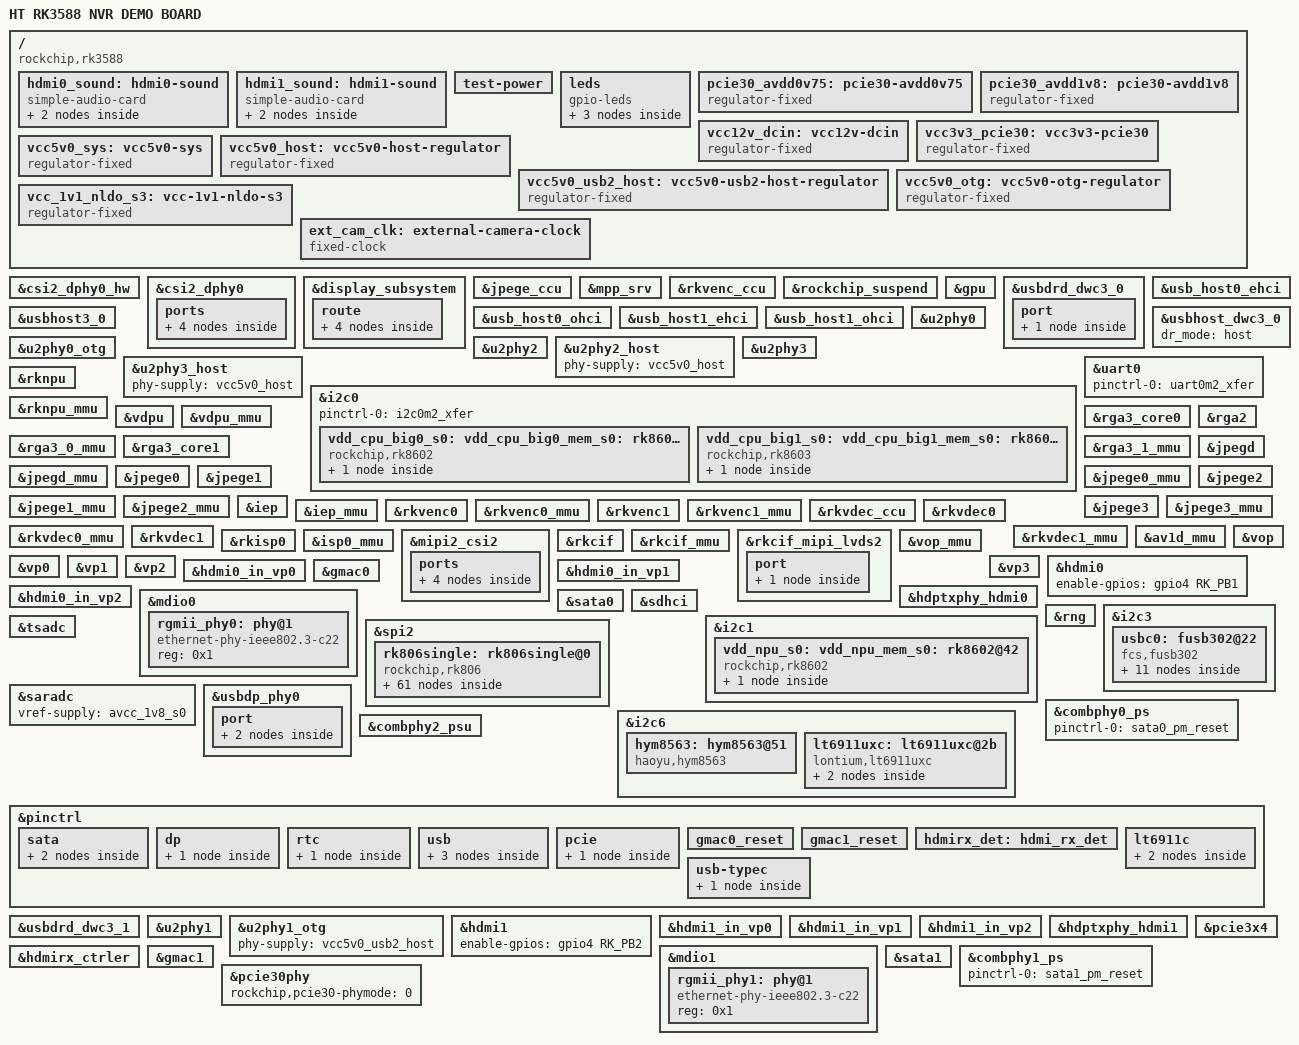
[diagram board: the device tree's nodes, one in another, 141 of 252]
// SPDX-License-Identifier: (GPL-2.0+ OR MIT)
/*
 * Copyright (c) 2026 Rockchip Electronics Co., Ltd.
 *
 */

/dts-v1/;


#include <dt-bindings/usb/pd.h>
#include "rk3588.dtsi"
#include "rk3588-nvr.dtsi"
#include "rk3588-linux.dtsi"

/ {
	serial-number = "b8003718ffaabed8";
	model = "HT RK3588 NVR DEMO BOARD";
	compatible = "rockchip,rk3588";

	hdmi0_sound: hdmi0-sound {
		status = "disabled";
		compatible = "simple-audio-card";
		simple-audio-card,format = "i2s";
		simple-audio-card,mclk-fs = <128>;
		simple-audio-card,name = "rockchip,hdmi0";

		simple-audio-card,cpu {
			sound-dai = <&i2s5_8ch>;
		};
		simple-audio-card,codec {
			sound-dai = <&hdmi0>;
		};
	};
	hdmi1_sound: hdmi1-sound {
		status = "disabled";
		compatible = "simple-audio-card";
		simple-audio-card,format = "i2s";
		simple-audio-card,mclk-fs = <128>;
		simple-audio-card,name = "rockchip,hdmi1";

		simple-audio-card,cpu {
			sound-dai = <&i2s6_8ch>;
		};
		simple-audio-card,codec {
			sound-dai = <&hdmi1>;
		};
	};
	test-power {
		status = "okay";
	};
	leds: leds {
		compatible = "gpio-leds";
		hdd_led: hdd-led {
			gpios = <&gpio3 RK_PC1 GPIO_ACTIVE_HIGH>;
			default-state = "off";
		};
		net_led: net-led {
			gpios = <&gpio3 RK_PC0 GPIO_ACTIVE_HIGH>;
			default-state = "off";
		};
		work_led: work-led {
			gpios = <&gpio3 RK_PB7 GPIO_ACTIVE_HIGH>;
			linux,default-trigger = "heartbeat";
		};
	};
	pcie30_avdd0v75: pcie30-avdd0v75 {
		compatible = "regulator-fixed";
		regulator-name = "pcie30_avdd0v75";
		regulator-boot-on;
		regulator-always-on;
		regulator-min-microvolt = <750000>;
		regulator-max-microvolt = <750000>;
		vin-supply = <&nldo5_s0>;
	};
	pcie30_avdd1v8: pcie30-avdd1v8 {
		compatible = "regulator-fixed";
		regulator-name = "pcie30_avdd1v8";
		regulator-boot-on;
		regulator-always-on;
		regulator-min-microvolt = <1800000>;
		regulator-max-microvolt = <1800000>;
		vin-supply = <&avcc_1v8_s0>;
	};
	vcc12v_dcin: vcc12v-dcin {
		compatible = "regulator-fixed";
		regulator-name = "vcc12v_dcin";
		regulator-always-on;
		regulator-boot-on;
		regulator-min-microvolt = <12000000>;
		regulator-max-microvolt = <12000000>;
	};
	vcc3v3_pcie30: vcc3v3-pcie30 {
		compatible = "regulator-fixed";
		regulator-name = "vcc3v3_pcie30";
		regulator-min-microvolt = <3300000>;
		regulator-max-microvolt = <3300000>;
		enable-active-high;
		gpios = <&gpio2 RK_PB4 GPIO_ACTIVE_HIGH>;
		startup-delay-us = <7500>;
		vin-supply = <&vcc12v_dcin>;
	};
	vcc5v0_sys: vcc5v0-sys {
		compatible = "regulator-fixed";
		regulator-name = "vcc5v0_sys";
		regulator-always-on;
		regulator-boot-on;
		regulator-min-microvolt = <5000000>;
		regulator-max-microvolt = <5000000>;
		vin-supply = <&vcc12v_dcin>;
	};
	vcc5v0_host: vcc5v0-host-regulator {
		compatible = "regulator-fixed";
		regulator-name = "vcc5v0_host";
		regulator-boot-on;
		regulator-always-on;
		regulator-min-microvolt = <5000000>;
		regulator-max-microvolt = <5000000>;
		enable-active-high;
		gpio = <&gpio3 RK_PC1 GPIO_ACTIVE_HIGH>;
		vin-supply = <&vcc5v0_sys>;
		pinctrl-names = "default";
		pinctrl-0 = <&vcc5v0_host_en>;
	};
	vcc5v0_usb2_host: vcc5v0-usb2-host-regulator {
		compatible = "regulator-fixed";
		regulator-name = "vcc5v0_usb2_host";
		regulator-boot-on;
		regulator-always-on;
		regulator-min-microvolt = <5000000>;
		regulator-max-microvolt = <5000000>;
		enable-active-high;
		gpio = <&gpio3 RK_PC0 GPIO_ACTIVE_HIGH>;
		vin-supply = <&vcc5v0_sys>;
		pinctrl-names = "default";
		pinctrl-0 = <&vcc5v0_usb2_host_en>;
	};
	vcc5v0_otg: vcc5v0-otg-regulator {
		compatible = "regulator-fixed";
		regulator-name = "vcc5v0_otg";
		regulator-min-microvolt = <5000000>;
		regulator-max-microvolt = <5000000>;
		enable-active-high;
		gpio = <&gpio4 RK_PA7 GPIO_ACTIVE_HIGH>;
		vin-supply = <&vcc5v0_sys>;
		pinctrl-names = "default";
		pinctrl-0 = <&vcc5v0_otg_en>;
	};
	vcc_1v1_nldo_s3: vcc-1v1-nldo-s3 {
		compatible = "regulator-fixed";
		regulator-name = "vcc_1v1_nldo_s3";
		regulator-always-on;
		regulator-boot-on;
		regulator-min-microvolt = <1100000>;
		regulator-max-microvolt = <1100000>;
		vin-supply = <&vcc5v0_sys>;
	};
	ext_cam_clk: external-camera-clock {
		status = "okay";
		compatible = "fixed-clock";
		clock-frequency = <27000000>;
		clock-output-names = "CLK_CAMERA_27MHZ";
		#clock-cells = <0>;
	};
};

&csi2_dphy0_hw {
	status = "okay";
};

&csi2_dphy0 {
	status = "okay";

	ports {
		#address-cells = <1>;
		#size-cells = <0>;

		port@0 {
			reg = <0>;
			#address-cells = <1>;
			#size-cells = <0>;

			hdmi_mipi_in: endpoint@1 {
				reg = <1>;
				remote-endpoint = <&lt6911uxc_out0>;
				data-lanes = <1 2>;
			};
		};

		port@1 {
			reg = <1>;
			#address-cells = <1>;
			#size-cells = <0>;

			csidphy0_out: endpoint@0 {
				reg = <0>;
				remote-endpoint = <&mipi2_csi2_input>;
			};
		};
	};
};

&display_subsystem {
	route {

		route_dp0: route-dp0 {
			status = "okay";
			logo,uboot = "logo.bmp";
			logo,kernel = "logo_kernel.bmp";
			logo,mode = "center";
			charge_logo,mode = "center";
			connect = <&vp2_out_dp0>;
		};

		route_hdmi0: route-hdmi0 {
			status = "okay";
			logo,uboot = "logo.bmp";
			logo,kernel = "logo_kernel.bmp";
			logo,mode = "center";
			charge_logo,mode = "center";
			connect = <&vp2_out_hdmi0>;
		};

		route_dp1: route-dp1 {
			status = "okay";
			logo,uboot = "logo.bmp";
			logo,kernel = "logo_kernel.bmp";
			logo,mode = "center";
			charge_logo,mode = "center";
			connect = <&vp2_out_dp1>;
		};

		route_hdmi1: route-hdmi1 {
			status = "okay";
			logo,uboot = "logo.bmp";
			logo,kernel = "logo_kernel.bmp";
			logo,mode = "center";
			charge_logo,mode = "center";
			connect = <&vp2_out_hdmi1>;
		};
	};
};
&jpege_ccu {
	status = "okay";
};
&mpp_srv {
	status = "okay";
};
&rkvenc_ccu {
	status = "okay";
};
&rockchip_suspend {
	status = "okay";
	rockchip,sleep-debug-en = <1>;
	rockchip,virtual-poweroff = <1>;
	rockchip,sleep-mode-config = <
		(0
		| RKPM_SLP_ARMOFF_DDRPD
		)
	>;
	rockchip,wakeup-config = <
		(0
		| RKPM_CPU0_WKUP_EN
		| RKPM_GPIO_WKUP_EN
		)
	>;
};
&gpu {
	mali-supply = <&vdd_gpu_s0>;
	mem-supply = <&vdd_gpu_mem_s0>;
	status = "okay";
};
&usbdrd_dwc3_0 {
	dr_mode = "otg";
	usb-role-switch;
	status = "okay";
	port {
		#address-cells = <1>;
		#size-cells = <0>;
		dwc3_0_role_switch: endpoint@0 {
			reg = <0>;
			remote-endpoint = <&usbc0_role_sw>;
		};
	};
};
&usb_host0_ehci {
	status = "okay";
};
&usb_host0_ohci {
	status = "okay";
};
&usb_host1_ehci {
	status = "okay";
};

&usb_host1_ohci {
	status = "okay";
};
&usbhost3_0 {
	status = "okay";
};
&usbhost_dwc3_0 {
	dr_mode = "host";
	status = "okay";
};
&u2phy0 {
	status = "okay";
};
&u2phy0_otg {
	vbus-supply = <&vcc5v0_otg>;
	rockchip,typec-vbus-det;
	status = "okay";
};
&u2phy2 {
	status = "okay";
};
&u2phy2_host {
	phy-supply = <&vcc5v0_host>;
	status = "okay";
};
&u2phy3 {
	status = "okay";
};
&u2phy3_host {
	phy-supply = <&vcc5v0_host>;
	status = "okay";
};
&i2c0 {
	status = "okay";
	pinctrl-names = "default";
	pinctrl-0 = <&i2c0m2_xfer>;
	
	vdd_cpu_big0_s0: vdd_cpu_big0_mem_s0: rk8602@42 {
		compatible = "rockchip,rk8602";
		reg = <0x42>;
		vin-supply = <&vcc5v0_sys>;
		regulator-compatible = "rk860x-reg";
		regulator-name = "vdd_cpu_big0_s0";
		regulator-min-microvolt = <550000>;
		regulator-max-microvolt = <1050000>;
		regulator-ramp-delay = <2300>;
		rockchip,suspend-voltage-selector = <1>;
		regulator-boot-on;
		regulator-always-on;
		regulator-state-mem {
			regulator-off-in-suspend;
		};
	};

	vdd_cpu_big1_s0: vdd_cpu_big1_mem_s0: rk8603@43 {
		compatible = "rockchip,rk8603";
		reg = <0x43>;
		vin-supply = <&vcc5v0_sys>;
		regulator-compatible = "rk860x-reg";
		regulator-name = "vdd_cpu_big1_s0";
		regulator-min-microvolt = <550000>;
		regulator-max-microvolt = <1050000>;
		regulator-ramp-delay = <2300>;
		rockchip,suspend-voltage-selector = <1>;
		regulator-boot-on;
		regulator-always-on;
		regulator-state-mem {
			regulator-off-in-suspend;
		};
	};
};
&uart0 {
    status = "okay";
    pinctrl-names = "default";
    pinctrl-0 = <&uart0m2_xfer>;

};
&rknpu {
	rknpu-supply = <&vdd_npu_s0>;
	mem-supply = <&vdd_npu_mem_s0>;
	status = "okay";
};
&rknpu_mmu {
	status = "okay";
};
&vdpu {
	status = "okay";
};

&vdpu_mmu {
	status = "okay";
};
&rga3_core0 {
	status = "okay";
};

&rga3_0_mmu {
	status = "okay";
};

&rga3_core1 {
	status = "okay";
};

&rga3_1_mmu {
	status = "okay";
};

&rga2 {
	status = "okay";
};
&jpegd {
	status = "okay";
};

&jpegd_mmu {
	status = "okay";
};
&jpege0 {
	status = "okay";
};
&jpege0_mmu {
	status = "okay";
};
&jpege1 {
	status = "okay";
};
&jpege1_mmu {
	status = "okay";
};
&jpege2 {
	status = "okay";
};
&jpege2_mmu {
	status = "okay";
};
&jpege3 {
	status = "okay";
};
&jpege3_mmu {
	status = "okay";
};
&iep {
	status = "okay";
};
&iep_mmu {
	status = "okay";
};
&rkvenc_ccu {
	status = "okay";
};
&rkvenc0 {
	status = "okay";
};
&rkvenc0_mmu {
	status = "okay";
};
&rkvenc1 {
	status = "okay";
};
&rkvenc1_mmu {
	status = "okay";
};
&rkvenc_ccu {
	status = "okay";
};
&rkvdec_ccu {
	status = "okay";
};
&rkvdec0 {
	status = "okay";
};
&rkvdec0_mmu {
	status = "okay";
};
&rkvdec1 {
	status = "okay";
};
&rkvdec1_mmu {
	status = "okay";
};
&av1d_mmu {
	status = "okay";
};
&rkisp0 {
	status = "okay";
};
&isp0_mmu {
	status = "okay";
};
&mipi2_csi2 {
	status = "okay";

	ports {
		#address-cells = <1>;
		#size-cells = <0>;

		port@0 {
			reg = <0>;
			#address-cells = <1>;
			#size-cells = <0>;

			mipi2_csi2_input: endpoint@1 {
				reg = <1>;
				remote-endpoint = <&csidphy0_out>;
			};
		};

		port@1 {
			reg = <1>;
			#address-cells = <1>;
			#size-cells = <0>;

			mipi2_csi2_output: endpoint@0 {
				reg = <0>;
				remote-endpoint = <&cif_mipi_in2>;
			};
		};
	};
};
&rkcif {
	status = "okay";
};
&rkcif_mmu {
	status = "okay";
};
&rkcif_mipi_lvds2 {
	status = "okay";

	port {
		cif_mipi_in2: endpoint {
			remote-endpoint = <&mipi2_csi2_output>;
		};
	};
};
&vop {
	assigned-clocks = <&cru ACLK_VOP>;
	assigned-clock-rates = <800000000>;
	status = "okay";
	skip-ref-fb;
};

&vop_mmu {
	status = "okay";
};

&vp0 {
	rockchip,plane-mask = <(1 << ROCKCHIP_VOP2_CLUSTER0 | 1 << ROCKCHIP_VOP2_ESMART0)>;
	rockchip,primary-plane = <ROCKCHIP_VOP2_ESMART0>;
};

&vp1 {
	rockchip,plane-mask = <(1 << ROCKCHIP_VOP2_CLUSTER1 | 1 << ROCKCHIP_VOP2_ESMART1)>;
	rockchip,primary-plane = <ROCKCHIP_VOP2_ESMART1>;
};

&vp2 {
	rockchip,plane-mask = <(1 << ROCKCHIP_VOP2_CLUSTER2 | 1 << ROCKCHIP_VOP2_ESMART2)>;
	rockchip,primary-plane = <ROCKCHIP_VOP2_ESMART2>;
};

&vp3 {
	rockchip,plane-mask = <(1 << ROCKCHIP_VOP2_CLUSTER3 | 1 << ROCKCHIP_VOP2_ESMART3)>;
	rockchip,primary-plane = <ROCKCHIP_VOP2_ESMART3>;

	assigned-clocks = <&cru DCLK_VOP3>;
	assigned-clock-parents = <&cru PLL_AUPLL>;
};
&vop_mmu {
	status = "okay";
};

&hdmi0 {
	enable-gpios = <&gpio4 RK_PB1 GPIO_ACTIVE_HIGH>;
	status = "okay";
};

&hdmi0_in_vp0 {
	status = "okay";
};

&hdmi0_in_vp1 {
	status = "okay";
};

&hdmi0_in_vp2 {
	status = "okay";
};
&hdmi0_sound {
	status = "okay";
};
&hdptxphy_hdmi0 {
	status = "okay";
};
&gmac0 {
	/* Use rgmii-rxid mode to disable rx delay inside Soc */
	phy-mode = "rgmii-rxid";
	clock_in_out = "output";

	snps,reset-gpio = <&gpio4 RK_PB3 GPIO_ACTIVE_LOW>;
	snps,reset-active-low;
	/* Reset time is 20ms, 100ms for rtl8211f */
	snps,reset-delays-us = <0 20000 100000>;

	pinctrl-names = "default";
	pinctrl-0 = <&gmac0_miim
		     &gmac0_tx_bus2
		     &gmac0_rx_bus2
		     &gmac0_rgmii_clk
		     &gmac0_rgmii_bus>;

	tx_delay = <0x44>;

	phy-handle = <&rgmii_phy0>;
	status = "okay";
};
&mdio0 {
	rgmii_phy0: phy@1 {
		compatible = "ethernet-phy-ieee802.3-c22";
		reg = <0x1>;
	};
};
&sata0 {
	status = "okay";
};
&sdhci {
	bus-width = <8>;
	no-sdio;
	no-sd;
	non-removable;
	max-frequency = <200000000>;
	mmc-hs400-1_8v;
	mmc-hs400-enhanced-strobe;
	status = "okay";
};
&rng {
	status = "okay";
};
&i2c1 {
	status = "okay";
	
	vdd_npu_s0: vdd_npu_mem_s0: rk8602@42 {
		compatible = "rockchip,rk8602";
		reg = <0x42>;
		vin-supply = <&vcc5v0_sys>;
		regulator-compatible = "rk860x-reg";
		regulator-name = "vdd_npu_s0";
		regulator-min-microvolt = <550000>;
		regulator-max-microvolt = <950000>;
		regulator-ramp-delay = <2300>;
		rockchip,suspend-voltage-selector = <1>;
		regulator-boot-on;
		regulator-always-on;
		regulator-state-mem {
			regulator-off-in-suspend;
		};
	};
};
&i2c3 {
	status = "okay";

	usbc0: fusb302@22 {
		compatible = "fcs,fusb302";
		reg = <0x22>;
		interrupt-parent = <&gpio1>;
		interrupts = <RK_PA0 IRQ_TYPE_LEVEL_LOW>;
		pinctrl-names = "default";
		pinctrl-0 = <&usbc0_int>;
		vbus-supply = <&vcc5v0_otg>;
		status = "okay";

		ports {
			#address-cells = <1>;
			#size-cells = <0>;

			port@0 {
				reg = <0>;
				usbc0_role_sw: endpoint@0 {
					remote-endpoint = <&dwc3_0_role_switch>;
				};
			};
		};

		usb_con: connector {
			compatible = "usb-c-connector";
			label = "USB-C";
			data-role = "dual";
			power-role = "dual";
			try-power-role = "sink";
			op-sink-microwatt = <1000000>;
			sink-pdos =
				<PDO_FIXED(5000, 1000, PDO_FIXED_USB_COMM)>;
			source-pdos =
				<PDO_FIXED(5000, 3000, PDO_FIXED_USB_COMM)>;

			altmodes {
				#address-cells = <1>;
				#size-cells = <0>;

				altmode@0 {
					reg = <0>;
					svid = <0xff01>;
					vdo = <0xffffffff>;
				};
			};

			ports {
				#address-cells = <1>;
				#size-cells = <0>;

				port@0 {
					reg = <0>;
					usbc0_orien_sw: endpoint {
						remote-endpoint = <&usbdp_phy0_orientation_switch>;
					};
				};

				port@1 {
					reg = <1>;
					dp_altmode_mux: endpoint {
						remote-endpoint = <&usbdp_phy0_dp_altmode_mux>;
					};
				};
			};
		};
	};
};
&spi2 {
	status = "okay";
	assigned-clocks = <&cru CLK_SPI2>;
	assigned-clock-rates = <200000000>;
	pinctrl-names = "default", "pmic-power-off";
	pinctrl-0 = <&pmic_pins>, <&rk806_dvs1_null>, <&rk806_dvs2_null>, <&rk806_dvs3_null>;
	pinctrl-1 = <&rk806_dvs1_slp>, <&rk806_dvs2_null>, <&rk806_dvs3_null>;
	num-cs = <1>;

	rk806single: rk806single@0 {
		compatible = "rockchip,rk806";
		spi-max-frequency = <1000000>;
		reg = <0x0>;

		interrupt-parent = <&gpio0>;
		interrupts = <7 IRQ_TYPE_LEVEL_LOW>;

		pinctrl-names = "default", "pmic-power-off";
		pinctrl-0 = <&pmic_pins>, <&rk806_dvs1_null>, <&rk806_dvs2_null>, <&rk806_dvs3_null>;
		pinctrl-1 = <&rk806_dvs1_pwrdn>;

		/* 2800mv-3500mv */
		low_voltage_threshold = <3000>;
		/* 2700mv-3400mv */
		shutdown_voltage_threshold = <2700>;
		/* 140 160 */
		shutdown_temperture_threshold = <160>;
		hotdie_temperture_threshold = <115>;

		/* 0: restart PMU;
		 * 1: reset all the power off reset registers,
		 *	forcing the state to switch to ACTIVE mode;
		 * 2: Reset all the power off reset registers,
		 *	forcing the state to switch to ACTIVE mode,
		 *	and simultaneously pull down the RESETB PIN for 5mS before releasing
		 */
		pmic-reset-func = <1>;

		vcc1-supply = <&vcc5v0_sys>;
		vcc2-supply = <&vcc5v0_sys>;
		vcc3-supply = <&vcc5v0_sys>;
		vcc4-supply = <&vcc5v0_sys>;
		vcc5-supply = <&vcc5v0_sys>;
		vcc6-supply = <&vcc5v0_sys>;
		vcc7-supply = <&vcc5v0_sys>;
		vcc8-supply = <&vcc5v0_sys>;
		vcc9-supply = <&vcc5v0_sys>;
		vcc10-supply = <&vcc5v0_sys>;
		vcc11-supply = <&vdd_2v0_pldo_s3>;
		vcc12-supply = <&vcc5v0_sys>;
		vcc13-supply = <&vcc_1v1_nldo_s3>;
		vcc14-supply = <&vcc_1v1_nldo_s3>;
		vcca-supply = <&vcc5v0_sys>;

		pwrkey {
			status = "okay";
		};

		pinctrl_rk806: pinctrl_rk806 {
			gpio-controller;
			#gpio-cells = <2>;

			rk806_dvs1_null: rk806_dvs1_null {
				pins = "gpio_pwrctrl2";
				function = "pin_fun0";
			};

			rk806_dvs1_slp: rk806_dvs1_slp {
				pins = "gpio_pwrctrl1";
				function = "pin_fun1";
			};

			rk806_dvs1_pwrdn: rk806_dvs1_pwrdn {
				pins = "gpio_pwrctrl1";
				function = "pin_fun2";
			};

			rk806_dvs1_rst: rk806_dvs1_rst {
				pins = "gpio_pwrctrl1";
				function = "pin_fun3";
			};

			rk806_dvs2_null: rk806_dvs2_null {
				pins = "gpio_pwrctrl2";
				function = "pin_fun0";
			};

			rk806_dvs2_slp: rk806_dvs2_slp {
				pins = "gpio_pwrctrl2";
				function = "pin_fun1";
			};

			rk806_dvs2_pwrdn: rk806_dvs2_pwrdn {
				pins = "gpio_pwrctrl2";
				function = "pin_fun2";
			};

			rk806_dvs2_rst: rk806_dvs2_rst {
				pins = "gpio_pwrctrl2";
				function = "pin_fun3";
			};

			rk806_dvs2_dvs: rk806_dvs2_dvs {
				pins = "gpio_pwrctrl2";
				function = "pin_fun4";
			};

			rk806_dvs2_gpio: rk806_dvs2_gpio {
				pins = "gpio_pwrctrl2";
				function = "pin_fun5";
			};

			rk806_dvs3_null: rk806_dvs3_null {
				pins = "gpio_pwrctrl3";
				function = "pin_fun0";
			};

			rk806_dvs3_slp: rk806_dvs3_slp {
				pins = "gpio_pwrctrl3";
				function = "pin_fun1";
			};

			rk806_dvs3_pwrdn: rk806_dvs3_pwrdn {
				pins = "gpio_pwrctrl3";
				function = "pin_fun2";
			};

			rk806_dvs3_rst: rk806_dvs3_rst {
				pins = "gpio_pwrctrl3";
				function = "pin_fun3";
			};

			rk806_dvs3_dvs: rk806_dvs3_dvs {
				pins = "gpio_pwrctrl3";
				function = "pin_fun4";
			};

			rk806_dvs3_gpio: rk806_dvs3_gpio {
				pins = "gpio_pwrctrl3";
				function = "pin_fun5";
			};
		};

		regulators {
			vdd_gpu_s0: vdd_gpu_mem_s0: DCDC_REG1 {
				regulator-always-on;
				regulator-boot-on;
				regulator-min-microvolt = <550000>;
				regulator-max-microvolt = <950000>;
				regulator-ramp-delay = <12500>;
				regulator-name = "vdd_gpu_s0";
				regulator-state-mem {
					regulator-off-in-suspend;
				};
			};

			vdd_cpu_lit_s0: vdd_cpu_lit_mem_s0: DCDC_REG2 {
				regulator-always-on;
				regulator-boot-on;
				regulator-min-microvolt = <550000>;
				regulator-max-microvolt = <950000>;
				regulator-ramp-delay = <12500>;
				regulator-name = "vdd_cpu_lit_s0";
				regulator-state-mem {
					regulator-off-in-suspend;
				};
			};

			vdd_log_s0: DCDC_REG3 {
				regulator-always-on;
				regulator-boot-on;
				regulator-min-microvolt = <750000>;
				regulator-max-microvolt = <750000>;
				regulator-ramp-delay = <12500>;
				regulator-name = "vdd_log_s0";
				regulator-state-mem {
					regulator-on-in-suspend;
				};
			};

			vdd_vdenc_s0: vdd_vdenc_mem_s0: DCDC_REG4 {
				regulator-always-on;
				regulator-boot-on;
				regulator-min-microvolt = <550000>;
				regulator-max-microvolt = <950000>;
				regulator-init-microvolt = <750000>;
				regulator-ramp-delay = <12500>;
				regulator-name = "vdd_vdenc_s0";
				regulator-state-mem {
					regulator-off-in-suspend;
				};
			};

			vdd_ddr_s0: DCDC_REG5 {
				regulator-always-on;
				regulator-boot-on;
				regulator-min-microvolt = <850000>;
				regulator-max-microvolt = <850000>;
				regulator-ramp-delay = <12500>;
				regulator-name = "vdd_ddr_s0";
				regulator-state-mem {
					regulator-off-in-suspend;
					regulator-suspend-microvolt = <850000>;
				};
			};

			vdd2_ddr_s3: DCDC_REG6 {
				regulator-always-on;
				regulator-boot-on;
				regulator-name = "vdd2_ddr_s3";
				regulator-state-mem {
					regulator-on-in-suspend;
				};
			};

			vdd_2v0_pldo_s3: DCDC_REG7 {
				regulator-always-on;
				regulator-boot-on;
				regulator-min-microvolt = <2000000>;
				regulator-max-microvolt = <2000000>;
				regulator-name = "vdd_2v0_pldo_s3";
				regulator-state-mem {
					regulator-on-in-suspend;
					regulator-suspend-microvolt = <2000000>;
				};
			};

			vcc_3v3_s3: DCDC_REG8 {
				regulator-always-on;
				regulator-boot-on;
				regulator-min-microvolt = <3300000>;
				regulator-max-microvolt = <3300000>;
				regulator-name = "vcc_3v3_s3";
				regulator-state-mem {
					regulator-on-in-suspend;
				};
			};

			vddq_ddr_s0: DCDC_REG9 {
				regulator-always-on;
				regulator-boot-on;
				regulator-name = "vddq_ddr_s0";
				regulator-state-mem {
					regulator-off-in-suspend;
				};
			};

			vcc_1v8_s3: DCDC_REG10 {
				regulator-always-on;
				regulator-boot-on;
				regulator-min-microvolt = <1800000>;
				regulator-max-microvolt = <1800000>;
				regulator-name = "vcc_1v8_s3";
				regulator-state-mem {
					regulator-on-in-suspend;
					regulator-suspend-microvolt = <1800000>;
				};
			};
			avcc_1v8_s0: PLDO_REG1 {
				regulator-always-on;
				regulator-boot-on;
				regulator-min-microvolt = <1800000>;
				regulator-max-microvolt = <1800000>;
				regulator-name = "avcc_1v8_s0";
				regulator-state-mem {
					regulator-on-in-suspend;
					regulator-suspend-microvolt = <1800000>;
				};
			};

			vcc_1v8_s0: PLDO_REG2 {
				regulator-always-on;
				regulator-boot-on;
				regulator-min-microvolt = <1800000>;
				regulator-max-microvolt = <1800000>;
				regulator-name = "vcc_1v8_s0";
				regulator-state-mem {
					regulator-off-in-suspend;
					regulator-suspend-microvolt = <1800000>;
				};
			};

			avdd_1v2_s0: PLDO_REG3 {
				regulator-always-on;
				regulator-boot-on;
				regulator-min-microvolt = <1200000>;
				regulator-max-microvolt = <1200000>;
				regulator-name = "avdd_1v2_s0";
				regulator-state-mem {
					regulator-off-in-suspend;
				};
			};

			vcc_3v3_s0: PLDO_REG4 {
				regulator-always-on;
				regulator-boot-on;
				regulator-min-microvolt = <3300000>;
				regulator-max-microvolt = <3300000>;
				regulator-name = "vcc_3v3_s0";
				regulator-state-mem {
					regulator-off-in-suspend;
				};
			};

			vccio_sd_s0: PLDO_REG5 {
				regulator-always-on;
				regulator-boot-on;
				regulator-min-microvolt = <1800000>;
				regulator-max-microvolt = <3300000>;
				regulator-name = "vccio_sd_s0";
				regulator-state-mem {
					regulator-off-in-suspend;
				};
			};

			pldo6_s3: PLDO_REG6 {
				regulator-always-on;
				regulator-boot-on;
				regulator-min-microvolt = <1800000>;
				regulator-max-microvolt = <1800000>;
				regulator-name = "pldo6_s3";
				regulator-state-mem {
					regulator-on-in-suspend;
					regulator-suspend-microvolt = <1800000>;
				};
			};

			vdd_0v75_s3: NLDO_REG1 {
				regulator-always-on;
				regulator-boot-on;
				regulator-min-microvolt = <750000>;
				regulator-max-microvolt = <750000>;
				regulator-name = "vdd_0v75_s3";
				regulator-state-mem {
					regulator-on-in-suspend;
					regulator-suspend-microvolt = <750000>;
				};
			};

			vdd_ddr_pll_s0: NLDO_REG2 {
				regulator-always-on;
				regulator-boot-on;
				regulator-min-microvolt = <850000>;
				regulator-max-microvolt = <850000>;
				regulator-name = "vdd_ddr_pll_s0";
				regulator-state-mem {
					regulator-off-in-suspend;
					regulator-suspend-microvolt = <850000>;
				};
			};

			avdd_0v75_s0: NLDO_REG3 {
				regulator-always-on;
				regulator-boot-on;
				regulator-min-microvolt = <837500>;
				regulator-max-microvolt = <837500>;
				regulator-name = "avdd_0v75_s0";
				regulator-state-mem {
					regulator-off-in-suspend;
				};
			};

			vdd_0v85_s0: NLDO_REG4 {
				regulator-always-on;
				regulator-boot-on;
				regulator-min-microvolt = <850000>;
				regulator-max-microvolt = <850000>;
				regulator-name = "vdd_0v85_s0";
				regulator-state-mem {
					regulator-off-in-suspend;
				};
			};

			nldo5_s0: NLDO_REG5 {
				regulator-always-on;
				regulator-boot-on;
				regulator-min-microvolt = <750000>;
				regulator-max-microvolt = <750000>;
				rregulator-name = "nldo5_s0";
				regulator-state-mem {
					regulator-off-in-suspend;
				};
			};
		};
	};
};
&tsadc {
	status = "okay";
};
&saradc {
	status = "okay";
	vref-supply = <&avcc_1v8_s0>;
};
&i2c6 {
	status = "okay";
	hym8563: hym8563@51 {
		compatible = "haoyu,hym8563";
		reg = <0x51>;

		pinctrl-names = "default";
		pinctrl-0 = <&rtc_int>;

		interrupt-parent = <&gpio2>;
		interrupts = <RK_PB5 IRQ_TYPE_LEVEL_LOW>;
		wakeup-source;
	};

    lt6911uxc: lt6911uxc@2b {
		status = "okay";
		compatible = "lontium,lt6911uxc";
		reg = <0x2b>;
		clocks = <&ext_cam_clk>;
		clock-names = "xvclk";
		reset-gpio = <&gpio4 RK_PA2 1>;
		interrupt-parent = <&gpio4>;
		interrupts = <RK_PA5 2>;
		rockchip,camera-module-index = <0>;
		rockchip,camera-module-facing = "back";
		rockchip,camera-module-name = "CMK-CT0116";
		rockchip,camera-module-lens-name = "Largan-50013A1";
		port {
			lt6911uxc_out0: endpoint {
				remote-endpoint = <&hdmi_mipi_in>;
				data-lanes = <1 2 3 4>;
			};
		};
	};
};
&usbdp_phy0 {
	status = "okay";
	rockchip,dp-lane-mux = < 0 1 2 3 >;
	orientation-switch;
	svid = <0xff01>;
	sbu1-dc-gpios = <&gpio0 RK_PC6 GPIO_ACTIVE_HIGH>;
	sbu2-dc-gpios = <&gpio0 RK_PD3 GPIO_ACTIVE_HIGH>;

	port {
		#address-cells = <1>;
		#size-cells = <0>;
		usbdp_phy0_orientation_switch: endpoint@0 {
			reg = <0>;
			remote-endpoint = <&usbc0_orien_sw>;
		};

		usbdp_phy0_dp_altmode_mux: endpoint@1 {
			reg = <1>;
			remote-endpoint = <&dp_altmode_mux>;
		};
	};

};
&combphy0_ps {
	pinctrl-names = "default";
	pinctrl-0 = <&sata0_pm_reset>;
	status = "okay";
};
&combphy2_psu {
	status = "okay";
};
&pinctrl {
	sata {
		sata0_pm_reset: sata0-pm-reset {
			rockchip,pins = <4 RK_PA0 RK_FUNC_GPIO &pcfg_output_high>;
		};
		sata1_pm_reset: sata1-pm-reset {
			rockchip,pins = <4 RK_PA1 RK_FUNC_GPIO &pcfg_output_high>;
		};
	};
	dp {
		dp1_hdmi_ctl: dp-hdmi-ctl {
			rockchip,pins = <0 RK_PD5 RK_FUNC_GPIO &pcfg_pull_up>,
							<3 RK_PB2 RK_FUNC_GPIO &pcfg_pull_up>;
		};
	};
	rtc {
		rtc_int: rtc-int {
			rockchip,pins = <2 RK_PB5 RK_FUNC_GPIO &pcfg_pull_up>;
		};
	};
	usb {
		vcc5v0_host_en: vcc5v0-host-en {
			rockchip,pins = <3 RK_PC1 RK_FUNC_GPIO &pcfg_pull_none>;
		};
		vcc5v0_usb2_host_en: vcc5v0-usb2-host-en {
			rockchip,pins = <3 RK_PC0 RK_FUNC_GPIO &pcfg_pull_none>;
		};
		vcc5v0_otg_en: vcc5v0-otg-en {
			rockchip,pins = <4 RK_PA7 RK_FUNC_GPIO &pcfg_pull_none>;
		};
	};
	pcie {
		power-en {
			rockchip,pins = <2 RK_PB4 RK_FUNC_GPIO &pcfg_output_high>;
		};
	};
	gmac0_reset {
		rockchip,pins = <4 RK_PB2 RK_FUNC_GPIO &pcfg_pull_up>;
	};
	gmac1_reset {
		rockchip,pins = <4 RK_PB3 RK_FUNC_GPIO &pcfg_pull_up>;
	};
	hdmirx_det: hdmi_rx_det {
		rockchip,pins = <0 RK_PA4 RK_FUNC_GPIO &pcfg_pull_up>;
	};
	lt6911c {
		lt6911c_irq {
			rockchip,pins = <4 RK_PA5 RK_FUNC_GPIO &pcfg_pull_none>;
		};
		lt6911c_rst {
			rockchip,pins = <4 RK_PA2 RK_FUNC_GPIO &pcfg_pull_none>;
		};
	};
	usb-typec {
		usbc0_int: usbc0-int {
			rockchip,pins = <1 RK_PA0 RK_FUNC_GPIO &pcfg_pull_up>;
		};
	};
};
&usbdrd_dwc3_1 {
	dr_mode = "host";
	maximum-speed = "high-speed";
	status = "okay";
};
&u2phy1 {
	status = "okay";
};
&u2phy1_otg {
	status = "okay";
	phy-supply = <&vcc5v0_usb2_host>;
};
&hdmi1 {
	enable-gpios = <&gpio4 RK_PB2 GPIO_ACTIVE_HIGH>;
	status = "okay";
};

&hdmi1_in_vp0 {
	status = "okay";
};

&hdmi1_in_vp1 {
	status = "okay";
};

&hdmi1_in_vp2 {
	status = "okay";
};
&hdmi1_sound {
	status = "okay";
};
&hdptxphy_hdmi1 {
	status = "okay";
};
&hdmirx_ctrler { 
	status = "okay"; 

	/* Effective level used to trigger HPD: 0-low, 1-high */ 
	hpd-trigger-level = <1>; 
	hdmirx-det-gpios = <&gpio0 RK_PA4 GPIO_ACTIVE_LOW>; 

	pinctrl-0 = <&hdmirx_det>;
}; 
&pcie3x4 {
	reset-gpios = <&gpio4 RK_PB6 GPIO_ACTIVE_HIGH>;
	vpcie3v3-supply = <&vcc3v3_pcie30>;
	status = "okay";
};
&gmac1 {
	/* Use rgmii-rxid mode to disable rx delay inside Soc */
	phy-mode = "rgmii-rxid";
	clock_in_out = "output";

	snps,reset-gpio = <&gpio4 RK_PA2 GPIO_ACTIVE_LOW>;
	snps,reset-active-low;
	/* Reset time is 20ms, 100ms for rtl8211f */
	snps,reset-delays-us = <0 20000 100000>;

	pinctrl-names = "default";
	pinctrl-0 = <&gmac1_miim
		     &gmac1_tx_bus2
		     &gmac1_rx_bus2
		     &gmac1_rgmii_clk
		     &gmac1_rgmii_bus>;

	tx_delay = <0x42>;

	phy-handle = <&rgmii_phy1>;
	status = "okay";
};
&mdio1 {
	rgmii_phy1: phy@1 {
		compatible = "ethernet-phy-ieee802.3-c22";
		reg = <0x1>;
	};
};
&sata1 {
	status = "okay";
};
&combphy1_ps {
	pinctrl-names = "default";
	pinctrl-0 = <&sata1_pm_reset>;
	status = "okay";
};
&pcie30phy {
	status = "okay";
	rockchip,pcie30-phymode = <0>;
};
